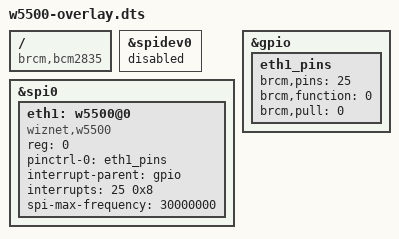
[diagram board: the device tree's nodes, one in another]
// Overlay for the Wiznet w5500 Ethernet Controller
/dts-v1/;
/plugin/;

/ {
	compatible = "brcm,bcm2835";

	fragment@0 {
		target = <&spidev0>;
		__overlay__ {
			status = "disabled";
		};
	};

	fragment@1 {
		target = <&spidev1>;
		__dormant__ {
			status = "disabled";
		};
	};

	fragment@2 {
		target = <&spi0>;
		__overlay__ {
			/* needed to avoid dtc warning */
			#address-cells = <1>;
			#size-cells = <0>;

			status = "okay";

			eth1: w5500@0{
				compatible = "wiznet,w5500";
				reg = <0>; /* CE0 */
				pinctrl-names = "default";
				pinctrl-0 = <&eth1_pins>;
				interrupt-parent = <&gpio>;
				interrupts = <25 0x8>;
				spi-max-frequency = <30000000>;
//				local-mac-address = [aa bb cc dd ee ff];
				status = "okay";
			};
		};
	};

	fragment@3 {
		target = <&gpio>;
		__overlay__ {
			eth1_pins: eth1_pins {
				brcm,pins = <25>;
				brcm,function = <0>; /* in */
				brcm,pull = <0>; /* none */
			};
		};
	};

	__overrides__ {
		int_pin = <&eth1>, "interrupts:0",
		          <&eth1_pins>, "brcm,pins:0";
		speed   = <&eth1>, "spi-max-frequency:0";
		cs      = <&eth1>, "reg:0",
			  <0>, "!0=1";
	};
};
